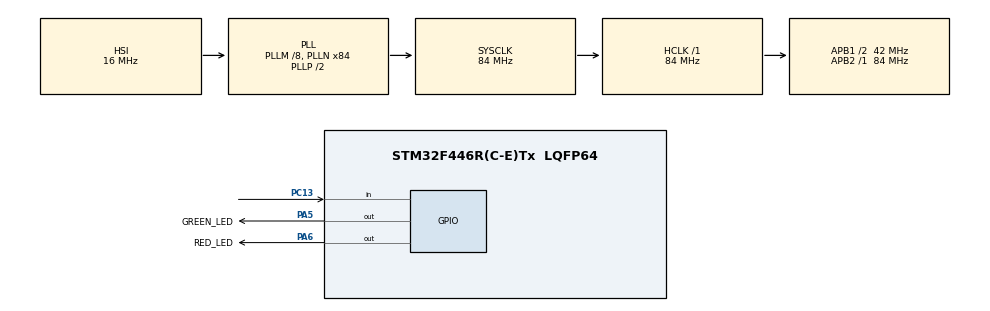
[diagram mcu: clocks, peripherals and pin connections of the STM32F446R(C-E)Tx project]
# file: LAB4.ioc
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FREERTOS.Tasks01=LightingTask,24,128,StartDefaultTask,Default,NULL,Dynamic,NULL,NULL;SecurityTask,40,128,StartTask02,Default,NULL,Dynamic,NULL,NULL
Mcu.Family=STM32F4
Mcu.Name=STM32F446R(C-E)Tx
Mcu.Package=LQFP64
NVIC.PriorityGroup=NVIC_PRIORITYGROUP_4
NVIC.TIM1_UP_TIM10_IRQn=true\:15\:0\:false\:false\:true\:false\:false\:true\:true
NVIC.TimeBase=TIM1_UP_TIM10_IRQn
NVIC.TimeBaseIP=TIM1
PA13.Mode=Trace_Asynchronous_SW
PA13.Signal=SYS_JTMS-SWDIO
PA14.Mode=Trace_Asynchronous_SW
PA14.Signal=SYS_JTCK-SWCLK
PA5.GPIO_Label=GREEN_LED
PA5.Signal=GPIO_Output
PA6.GPIO_Label=RED_LED
PA6.Signal=GPIO_Output
PB3.Mode=Trace_Asynchronous_SW
PB3.Signal=SYS_JTDO-SWO
PC13.GPIO_PuPd=GPIO_PULLUP
PC13.Signal=GPIO_Input
ProjectManager.HeapSize=0x200
ProjectManager.StackSize=0x400
ProjectManager.TargetToolchain=STM32CubeIDE
RCC.AHBFreq_Value=84000000
RCC.APB1CLKDivider=RCC_HCLK_DIV2
RCC.APB1Freq_Value=42000000
RCC.APB1TimFreq_Value=84000000
RCC.APB2Freq_Value=84000000
RCC.APB2TimFreq_Value=84000000
RCC.CortexFreq_Value=84000000
RCC.HCLKFreq_Value=84000000
RCC.PLLM=8
RCC.PLLN=84
RCC.SYSCLKFreq_VALUE=84000000
RCC.SYSCLKSource=RCC_SYSCLKSOURCE_PLLCLK
RCC.USBFreq_Value=84000000
RCC.VCOOutputFreq_Value=168000000
VP_FREERTOS_VS_CMSIS_V2.Mode=CMSIS_V2
VP_SYS_VS_tim1.Mode=TIM1
board=custom

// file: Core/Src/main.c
/* USER CODE BEGIN Header */
/**
  ******************************************************************************
  * @file           : main.c
  * @brief          : Main program body
  ******************************************************************************
  * @attention
  *
  * Copyright (c) 2026 STMicroelectronics.
  * All rights reserved.
  *
  * This software is licensed under terms that can be found in the LICENSE file
  * in the root directory of this software component.
  * If no LICENSE file comes with this software, it is provided AS-IS.
  *
  ******************************************************************************
  */
/* USER CODE END Header */
#include "main.h"
#include "cmsis_os.h"

/* Definitions for LightingTask */
osThreadId_t LightingTaskHandle;
const osThreadAttr_t LightingTask_attributes = {
  .name = "LightingTask",
  .stack_size = 128 * 4,
  .priority = (osPriority_t) osPriorityNormal,
};
/* Definitions for SecurityTask */
osThreadId_t SecurityTaskHandle;
const osThreadAttr_t SecurityTask_attributes = {
  .name = "SecurityTask",
  .stack_size = 128 * 4,
  .priority = (osPriority_t) osPriorityHigh,
};

void SystemClock_Config(void);
static void MX_GPIO_Init(void);
void StartDefaultTask(void *argument);
void StartTask02(void *argument);

int main(void)
{

  /* MCU Configuration--------------------------------------------------------*/

  /* Reset of all peripherals, Initializes the Flash interface and the Systick. */
  HAL_Init();

  /* Configure the system clock */
  SystemClock_Config();

  /* Initialize all configured peripherals */
  MX_GPIO_Init();

  /* Init scheduler */
  osKernelInitialize();

  /* Create the thread(s) */
  /* creation of LightingTask */
  LightingTaskHandle = osThreadNew(StartDefaultTask, NULL, &LightingTask_attributes);

  /* creation of SecurityTask */
  SecurityTaskHandle = osThreadNew(StartTask02, NULL, &SecurityTask_attributes);

  /* Start scheduler */
  osKernelStart();

  /* We should never get here as control is now taken by the scheduler */

  /* Infinite loop */
  while (1)
  {

  }
}

void SystemClock_Config(void)
{
  RCC_OscInitTypeDef RCC_OscInitStruct = {0};
  RCC_ClkInitTypeDef RCC_ClkInitStruct = {0};

  /** Configure the main internal regulator output voltage
  */
  __HAL_RCC_PWR_CLK_ENABLE();
  __HAL_PWR_VOLTAGESCALING_CONFIG(PWR_REGULATOR_VOLTAGE_SCALE3);

  /** Initializes the RCC Oscillators according to the specified parameters
  * in the RCC_OscInitTypeDef structure.
  */
  RCC_OscInitStruct.OscillatorType = RCC_OSCILLATORTYPE_HSI;
  RCC_OscInitStruct.HSIState = RCC_HSI_ON;
  RCC_OscInitStruct.HSICalibrationValue = RCC_HSICALIBRATION_DEFAULT;
  RCC_OscInitStruct.PLL.PLLState = RCC_PLL_ON;
  RCC_OscInitStruct.PLL.PLLSource = RCC_PLLSOURCE_HSI;
  RCC_OscInitStruct.PLL.PLLM = 8;
  RCC_OscInitStruct.PLL.PLLN = 84;
  RCC_OscInitStruct.PLL.PLLP = RCC_PLLP_DIV2;
  RCC_OscInitStruct.PLL.PLLQ = 2;
  RCC_OscInitStruct.PLL.PLLR = 2;
  if (HAL_RCC_OscConfig(&RCC_OscInitStruct) != HAL_OK)
  {
    Error_Handler();
  }

  /** Initializes the CPU, AHB and APB buses clocks
  */
  RCC_ClkInitStruct.ClockType = RCC_CLOCKTYPE_HCLK|RCC_CLOCKTYPE_SYSCLK
                              |RCC_CLOCKTYPE_PCLK1|RCC_CLOCKTYPE_PCLK2;
  RCC_ClkInitStruct.SYSCLKSource = RCC_SYSCLKSOURCE_PLLCLK;
  RCC_ClkInitStruct.AHBCLKDivider = RCC_SYSCLK_DIV1;
  RCC_ClkInitStruct.APB1CLKDivider = RCC_HCLK_DIV2;
  RCC_ClkInitStruct.APB2CLKDivider = RCC_HCLK_DIV1;

  if (HAL_RCC_ClockConfig(&RCC_ClkInitStruct, FLASH_LATENCY_2) != HAL_OK)
  {
    Error_Handler();
  }
}

static void MX_GPIO_Init(void)
{
  GPIO_InitTypeDef GPIO_InitStruct = {0};

  /* GPIO Ports Clock Enable */
  __HAL_RCC_GPIOC_CLK_ENABLE();
  __HAL_RCC_GPIOA_CLK_ENABLE();
  __HAL_RCC_GPIOB_CLK_ENABLE();

  /*Configure GPIO pin Output Level */
  HAL_GPIO_WritePin(GPIOA, GREEN_LED_Pin|RED_LED_Pin, GPIO_PIN_RESET);

  /*Configure GPIO pin : PC13 */
  GPIO_InitStruct.Pin = GPIO_PIN_13;
  GPIO_InitStruct.Mode = GPIO_MODE_INPUT;
  GPIO_InitStruct.Pull = GPIO_PULLUP;
  HAL_GPIO_Init(GPIOC, &GPIO_InitStruct);

  /*Configure GPIO pins : GREEN_LED_Pin RED_LED_Pin */
  GPIO_InitStruct.Pin = GREEN_LED_Pin|RED_LED_Pin;
  GPIO_InitStruct.Mode = GPIO_MODE_OUTPUT_PP;
  GPIO_InitStruct.Pull = GPIO_NOPULL;
  GPIO_InitStruct.Speed = GPIO_SPEED_FREQ_LOW;
  HAL_GPIO_Init(GPIOA, &GPIO_InitStruct);

}

void StartDefaultTask(void *argument)
{
  /* USER CODE BEGIN 5 */
  /* Infinite loop */
  for(;;)
  {
    // Blink the Green LED to show everything is normal at home
    HAL_GPIO_TogglePin(GPIOA, GREEN_LED_Pin);

    // Sleep for 500ms
    osDelay(500);
  }
  /* USER CODE END 5 */
}

void StartTask02(void *argument)
{
  /* USER CODE BEGIN StartTask02 */
  /* Infinite loop */
  for(;;)
  {
    // MODIFIED LINE: Built-in Nucleo button reads HIGH (SET) when pressed!
    if(HAL_GPIO_ReadPin(GPIOC, GPIO_PIN_13) == GPIO_PIN_SET)
    {
      // INTRUDER DETECTED!
      HAL_GPIO_WritePin(GPIOA, GREEN_LED_Pin, GPIO_PIN_RESET); // Instantly KILL the green light
      HAL_GPIO_WritePin(GPIOA, RED_LED_Pin, GPIO_PIN_SET);     // Turn ON the red alarm light

      // Keep the alarm active and freeze the house for 2 full seconds
      osDelay(2000);
    }
    else
    {
      // Safe mode: Keep the red alarm LED turned off
      HAL_GPIO_WritePin(GPIOA, RED_LED_Pin, GPIO_PIN_RESET);

      // CRUCIAL: High priority tasks MUST sleep briefly if nothing is happening
      osDelay(10);
    }
  }
  /* USER CODE END StartTask02 */
}

void HAL_TIM_PeriodElapsedCallback(TIM_HandleTypeDef *htim)
{
  if (htim->Instance == TIM1)
  {
    HAL_IncTick();
  }
}

void Error_Handler(void)
{
  __disable_irq();
  while (1)
  {
  }
}
